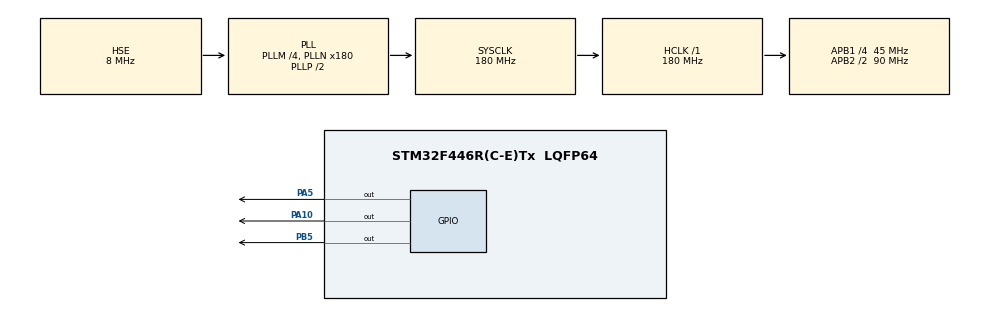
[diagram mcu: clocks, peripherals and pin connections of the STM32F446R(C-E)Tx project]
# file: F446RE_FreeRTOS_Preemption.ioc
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FREERTOS.Tasks01=Task1,8,128,StartTask1,Default,NULL,Dynamic,NULL,NULL;Task2,16,128,StartTask2,Default,NULL,Dynamic,NULL,NULL;Task3,24,128,StartTask3,Default,NULL,Dynamic,NULL,NULL;Task4,32,128,StartTask4,Default,NULL,Dynamic,NULL,NULL
FREERTOS.configUSE_NEWLIB_REENTRANT=1
Mcu.Family=STM32F4
Mcu.Name=STM32F446R(C-E)Tx
Mcu.Package=LQFP64
NVIC.PriorityGroup=NVIC_PRIORITYGROUP_4
NVIC.TIM6_DAC_IRQn=true\:15\:0\:false\:false\:true\:false\:false\:true\:true
NVIC.TimeBase=TIM6_DAC_IRQn
NVIC.TimeBaseIP=TIM6
PA10.Signal=GPIO_Output
PA13.Mode=Serial_Wire
PA13.Signal=SYS_JTMS-SWDIO
PA14.Mode=Serial_Wire
PA14.Signal=SYS_JTCK-SWCLK
PA5.Signal=GPIO_Output
PB5.Signal=GPIO_Output
PH0-OSC_IN.Mode=HSE-External-Clock-Source
PH0-OSC_IN.Signal=RCC_OSC_IN
PH1-OSC_OUT.Mode=HSE-External-Clock-Source
PH1-OSC_OUT.Signal=RCC_OSC_OUT
ProjectManager.HeapSize=0x200
ProjectManager.StackSize=0x400
ProjectManager.TargetToolchain=STM32CubeIDE
RCC.AHBFreq_Value=180000000
RCC.APB1CLKDivider=RCC_HCLK_DIV4
RCC.APB1Freq_Value=45000000
RCC.APB1TimFreq_Value=90000000
RCC.APB2CLKDivider=RCC_HCLK_DIV2
RCC.APB2Freq_Value=90000000
RCC.APB2TimFreq_Value=180000000
RCC.CortexFreq_Value=180000000
RCC.HCLKFreq_Value=180000000
RCC.HSE_VALUE=8000000
RCC.PLLM=4
RCC.PLLN=180
RCC.PLLSourceVirtual=RCC_PLLSOURCE_HSE
RCC.SYSCLKFreq_VALUE=180000000
RCC.SYSCLKSource=RCC_SYSCLKSOURCE_PLLCLK
RCC.USBFreq_Value=180000000
RCC.VCOOutputFreq_Value=360000000
VP_FREERTOS_VS_CMSIS_V2.Mode=CMSIS_V2
VP_SYS_VS_tim6.Mode=TIM6
board=custom

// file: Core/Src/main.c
/* USER CODE BEGIN Header */
/**
  ******************************************************************************
  * @file           : main.c
  * @brief          : Main program body
  ******************************************************************************
  * @attention
  *
  * Copyright (c) 2026 STMicroelectronics.
  * All rights reserved.
  *
  * This software is licensed under terms that can be found in the LICENSE file
  * in the root directory of this software component.
  * If no LICENSE file comes with this software, it is provided AS-IS.
  *
  ******************************************************************************
  */
/* USER CODE END Header */
#include "main.h"
#include "cmsis_os.h"

/* Definitions for Task1 */
osThreadId_t Task1Handle;
const osThreadAttr_t Task1_attributes = {
  .name = "Task1",
  .stack_size = 128 * 4,
  .priority = (osPriority_t) osPriorityLow,
};
/* Definitions for Task2 */
osThreadId_t Task2Handle;
const osThreadAttr_t Task2_attributes = {
  .name = "Task2",
  .stack_size = 128 * 4,
  .priority = (osPriority_t) osPriorityBelowNormal,
};
/* Definitions for Task3 */
osThreadId_t Task3Handle;
const osThreadAttr_t Task3_attributes = {
  .name = "Task3",
  .stack_size = 128 * 4,
  .priority = (osPriority_t) osPriorityNormal,
};
/* Definitions for Task4 */
osThreadId_t Task4Handle;
const osThreadAttr_t Task4_attributes = {
  .name = "Task4",
  .stack_size = 128 * 4,
  .priority = (osPriority_t) osPriorityAboveNormal,
};

void SystemClock_Config(void);
static void MX_GPIO_Init(void);
void StartTask1(void *argument);
void StartTask2(void *argument);
void StartTask3(void *argument);
void StartTask4(void *argument);

int main(void)
{

  /* MCU Configuration--------------------------------------------------------*/

  /* Reset of all peripherals, Initializes the Flash interface and the Systick. */
  HAL_Init();

  /* Configure the system clock */
  SystemClock_Config();

  /* Initialize all configured peripherals */
  MX_GPIO_Init();

  /* Init scheduler */
  osKernelInitialize();

  /* Create the thread(s) */
  /* creation of Task1 */
  Task1Handle = osThreadNew(StartTask1, NULL, &Task1_attributes);

  /* creation of Task2 */
  Task2Handle = osThreadNew(StartTask2, NULL, &Task2_attributes);

  /* creation of Task3 */
  Task3Handle = osThreadNew(StartTask3, NULL, &Task3_attributes);

  /* creation of Task4 */
  Task4Handle = osThreadNew(StartTask4, NULL, &Task4_attributes);

  /* Start scheduler */
  osKernelStart();

  /* We should never get here as control is now taken by the scheduler */

  /* Infinite loop */
  while (1)
  {

  }
}

void SystemClock_Config(void)
{
  RCC_OscInitTypeDef RCC_OscInitStruct = {0};
  RCC_ClkInitTypeDef RCC_ClkInitStruct = {0};

  /** Configure the main internal regulator output voltage
  */
  __HAL_RCC_PWR_CLK_ENABLE();
  __HAL_PWR_VOLTAGESCALING_CONFIG(PWR_REGULATOR_VOLTAGE_SCALE1);

  /** Initializes the RCC Oscillators according to the specified parameters
  * in the RCC_OscInitTypeDef structure.
  */
  RCC_OscInitStruct.OscillatorType = RCC_OSCILLATORTYPE_HSE;
  RCC_OscInitStruct.HSEState = RCC_HSE_BYPASS;
  RCC_OscInitStruct.PLL.PLLState = RCC_PLL_ON;
  RCC_OscInitStruct.PLL.PLLSource = RCC_PLLSOURCE_HSE;
  RCC_OscInitStruct.PLL.PLLM = 4;
  RCC_OscInitStruct.PLL.PLLN = 180;
  RCC_OscInitStruct.PLL.PLLP = RCC_PLLP_DIV2;
  RCC_OscInitStruct.PLL.PLLQ = 2;
  RCC_OscInitStruct.PLL.PLLR = 2;
  if (HAL_RCC_OscConfig(&RCC_OscInitStruct) != HAL_OK)
  {
    Error_Handler();
  }

  /** Activate the Over-Drive mode
  */
  if (HAL_PWREx_EnableOverDrive() != HAL_OK)
  {
    Error_Handler();
  }

  /** Initializes the CPU, AHB and APB buses clocks
  */
  RCC_ClkInitStruct.ClockType = RCC_CLOCKTYPE_HCLK|RCC_CLOCKTYPE_SYSCLK
                              |RCC_CLOCKTYPE_PCLK1|RCC_CLOCKTYPE_PCLK2;
  RCC_ClkInitStruct.SYSCLKSource = RCC_SYSCLKSOURCE_PLLCLK;
  RCC_ClkInitStruct.AHBCLKDivider = RCC_SYSCLK_DIV1;
  RCC_ClkInitStruct.APB1CLKDivider = RCC_HCLK_DIV4;
  RCC_ClkInitStruct.APB2CLKDivider = RCC_HCLK_DIV2;

  if (HAL_RCC_ClockConfig(&RCC_ClkInitStruct, FLASH_LATENCY_5) != HAL_OK)
  {
    Error_Handler();
  }
}

static void MX_GPIO_Init(void)
{
  GPIO_InitTypeDef GPIO_InitStruct = {0};

  /* GPIO Ports Clock Enable */
  __HAL_RCC_GPIOH_CLK_ENABLE();
  __HAL_RCC_GPIOA_CLK_ENABLE();
  __HAL_RCC_GPIOB_CLK_ENABLE();

  /*Configure GPIO pin Output Level */
  HAL_GPIO_WritePin(GPIOA, GPIO_PIN_5|GPIO_PIN_10, GPIO_PIN_RESET);

  /*Configure GPIO pin Output Level */
  HAL_GPIO_WritePin(GPIOB, GPIO_PIN_5, GPIO_PIN_RESET);

  /*Configure GPIO pins : PA5 PA10 */
  GPIO_InitStruct.Pin = GPIO_PIN_5|GPIO_PIN_10;
  GPIO_InitStruct.Mode = GPIO_MODE_OUTPUT_PP;
  GPIO_InitStruct.Pull = GPIO_NOPULL;
  GPIO_InitStruct.Speed = GPIO_SPEED_FREQ_LOW;
  HAL_GPIO_Init(GPIOA, &GPIO_InitStruct);

  /*Configure GPIO pin : PB5 */
  GPIO_InitStruct.Pin = GPIO_PIN_5;
  GPIO_InitStruct.Mode = GPIO_MODE_OUTPUT_PP;
  GPIO_InitStruct.Pull = GPIO_NOPULL;
  GPIO_InitStruct.Speed = GPIO_SPEED_FREQ_LOW;
  HAL_GPIO_Init(GPIOB, &GPIO_InitStruct);

}

void StartTask1(void *argument)
{
  /* USER CODE BEGIN 5 */

	//lowest prio task: blink every 1s. Due to task 2 preempting task 1, the red led seems to blink at the same rate as task2's blue led.
	// this is because task1 only gets to run when no higher order task is running, meaning only when task2,3,4 are in waiting/blocked state

  /* Infinite loop */
  for(;;)
  {
	  HAL_GPIO_TogglePin(GPIOB, GPIO_PIN_5);
	  osDelay(1000);	//blocks the task for 1s, task is in Waiting state until delay over or event happens, let other tasks run
  }
  /* USER CODE END 5 */
}

void StartTask2(void *argument)
{
  /* USER CODE BEGIN StartTask2 */

	//mid prio task: blink every 500ms, due to the simulated cpu hogging, led will blink at much slower rate

  /* Infinite loop */
  for(;;)
  {
	  HAL_GPIO_TogglePin(GPIOA, GPIO_PIN_10);
	  osDelay(500);

	  //represent 50 millions cycles processing time. lower prio task get starved, higher prio can preempts this task
	  volatile uint32_t wait = 50000000;	//volatile: var can change at anytime without any current code action (due to hardware, ISR, etc)
	  while(wait--);						//the modifier tells compiler not to optimize the var (store in cache), but read directly from memory
  }
  /* USER CODE END StartTask2 */
}

void StartTask3(void *argument)
{
  /* USER CODE BEGIN StartTask3 */

	//high prio task: blink every 200ms

	//	When two tasks share the same priority and both are in the ready state, FreeRTOS will switch between them
	//	using round-robin scheduling — giving each one an equal slice of CPU time. Just make sure both tasks call
	//	osDelay() at some point, otherwise one task can starve the other.

  /* Infinite loop */
  for(;;)
  {
	  HAL_GPIO_TogglePin(GPIOA, GPIO_PIN_5);
	  osDelay(200);
  }
  /* USER CODE END StartTask3 */
}

void StartTask4(void *argument)
{
  /* USER CODE BEGIN StartTask4 */

	//highest prio task: control task 3 lifecycle using osThreadSuspend() and osThreadResume()
	//suspended task is still fully stored in the heap memory and can be resumed again.

	//osThreadTerminate() - permanently delete the task and free the memory, use for one time init tasks
	//osThreadGetId() - returns the ID of the currently running thread(task)
	//osThreadGetState() - queries the current state of any thread (running, ready, blocked)
	//osThreadGetPriority() - reads the current priority of any thread
	//osThreadSetPriority() - changes it during runtime

  /* Infinite loop */
  for(;;)
  {
	    osDelay(1000);
	    osThreadSuspend(Task3Handle);
	    osDelay(5000);
	    osThreadResume(Task3Handle);
  }
  /* USER CODE END StartTask4 */
}

void HAL_TIM_PeriodElapsedCallback(TIM_HandleTypeDef *htim)
{
  if (htim->Instance == TIM6)
  {
    HAL_IncTick();
  }
}

void Error_Handler(void)
{
  __disable_irq();
  while (1)
  {
  }
}
